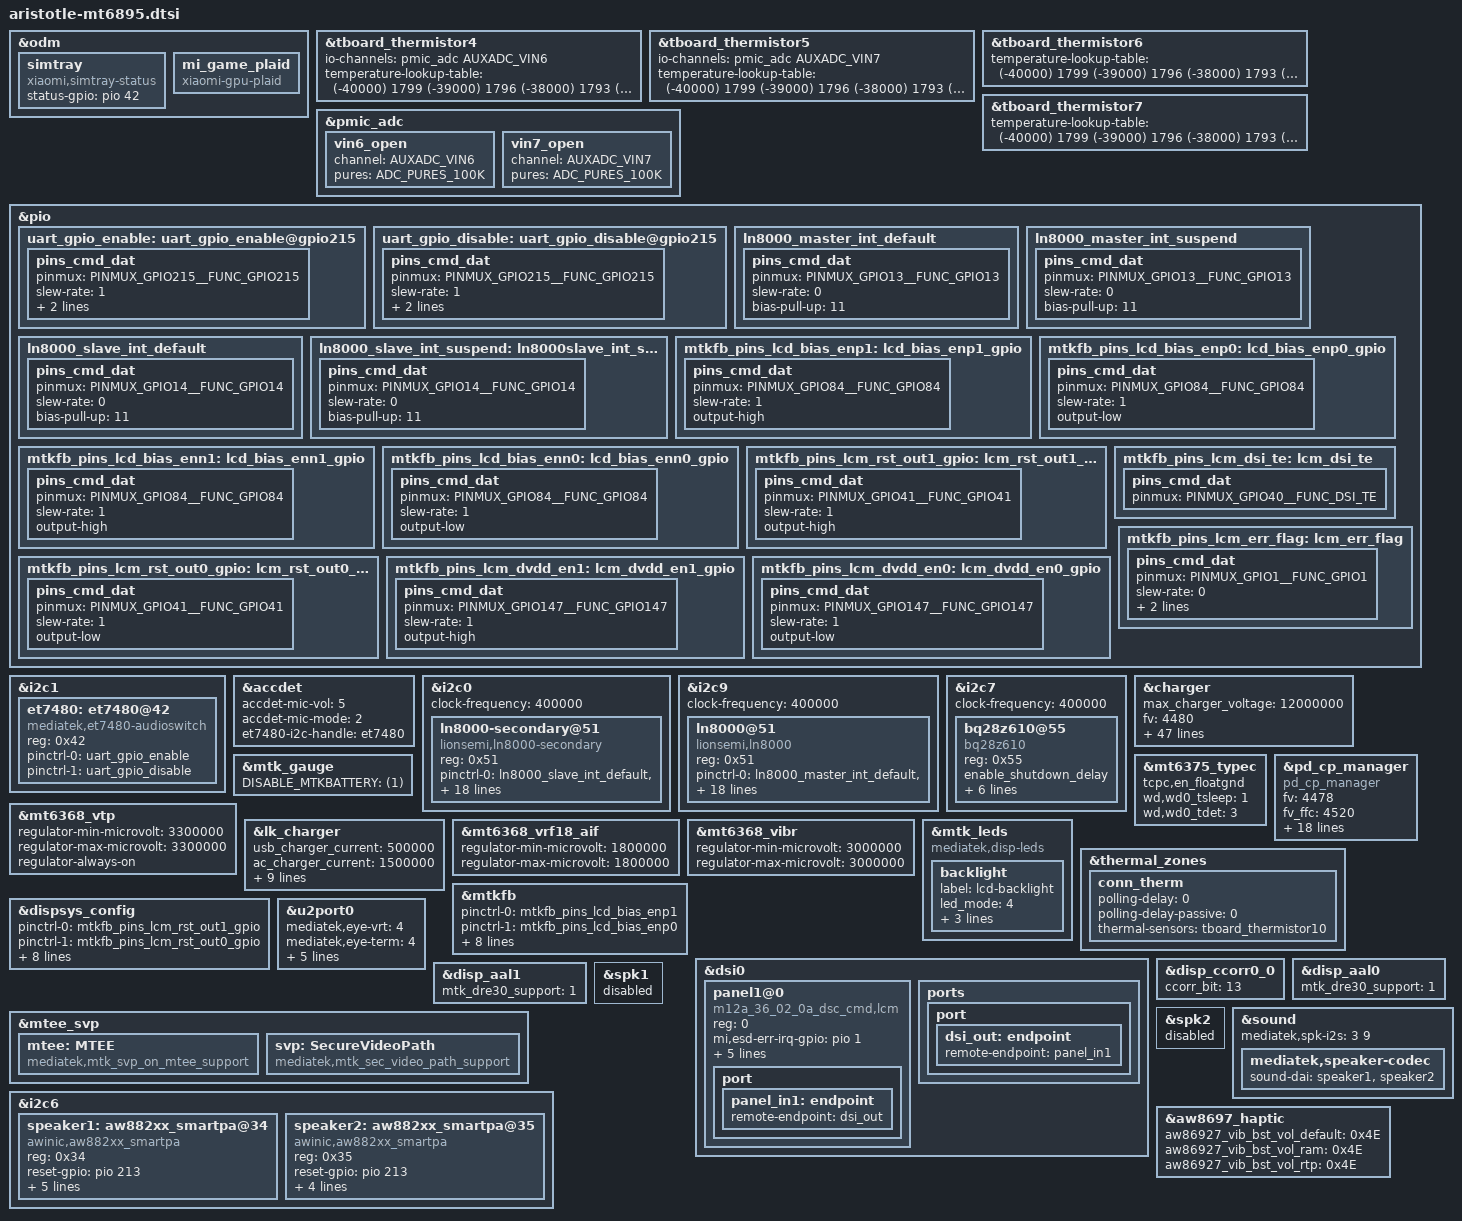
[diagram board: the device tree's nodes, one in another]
/*
this file is only for attribution of aristotle
*/
#include "mediatek/xiaomi-mt6895-common.dtsi"
#include "mediatek/aristotle_mt6895_camera_v4l2.dtsi"
#include "mediatek/xiaomi-aristotle-mt6895-fingerprint.dtsi"
#include "mediatek/xiaomi_aristotle_mt6895_touch.dtsi"
#include <dt-bindings/iio/mt635x-auxadc.h>
#include <dt-bindings/thermal/thermal.h>

&odm {
	simtray {
		compatible = "xiaomi,simtray-status";
		status-gpio =	<&pio 42 0>;
	};
};
&tboard_thermistor4{
	io-channels =<&pmic_adc AUXADC_VIN6>;
	temperature-lookup-table = <
		(-40000) 1799
		(-39000) 1796
		(-38000) 1793
		(-37000) 1790
		(-36000) 1786
		(-35000) 1783
		(-34000) 1779
		(-33000) 1775
		(-32000) 1769
		(-31000) 1765
		(-30000) 1760
		(-29000) 1754
		(-28000) 1749
		(-27000) 1743
		(-26000) 1737
		(-25000) 1731
		(-24000) 1723
		(-23000) 1716
		(-22000) 1709
		(-21000) 1701
		(-20000) 1693
		(-19000) 1685
		(-18000) 1675
		(-17000) 1666
		(-16000) 1656
		(-15000) 1646
		(-14000) 1635
		(-13000) 1623
		(-12000) 1612
		(-11000) 1600
		(-10000) 1588
		(-9000) 1574
		(-8000) 1561
		(-7000) 1548
		(-6000) 1533
		(-5000) 1518
		(-4000) 1503
		(-3000) 1487
		(-2000) 1471
		(-1000) 1455
		0 1437
		1000 1420
		2000 1402
		3000 1384
		4000 1365
		5000 1346
		6000 1327
		7000 1307
		8000 1287
		9000 1267
		10000 1246
		11000 1225
		12000 1204
		13000 1183
		14000 1161
		15000 1140
		16000 1117
		17000 1096
		18000 1073
		19000 1052
		20000 1029
		21000 1008
		22000 985
		23000 964
		24000 941
		25000 920
		26000 899
		27000 877
		28000 856
		29000 834
		30000 814
		31000 792
		32000 772
		33000 752
		34000 732
		35000 712
		36000 693
		37000 674
		38000 655
		39000 637
		40000 618
		41000 601
		42000 584
		43000 567
		44000 550
		45000 535
		46000 518
		47000 503
		48000 488
		49000 473
		50000 459
		51000 445
		52000 431
		53000 418
		54000 405
		55000 393
		56000 380
		57000 368
		58000 357
		59000 346
		60000 334
		61000 324
		62000 314
		63000 304
		64000 294
		65000 285
		66000 276
		67000 267
		68000 259
		69000 250
		70000 242
		71000 235
		72000 227
		73000 220
		74000 214
		75000 206
		76000 200
		77000 193
		78000 187
		79000 182
		80000 176
		81000 171
		82000 165
		83000 159
		84000 154
		85000 150
		86000 145
		87000 141
		88000 136
		89000 132
		90000 128
		91000 124
		92000 121
		93000 117
		94000 113
		95000 109
		96000 106
		97000 103
		98000 100
		99000 97
		100000 94
		101000 91
		102000 89
		103000 86
		104000 83
		105000 81
		106000 79
		107000 76
		108000 74
		109000 72
		110000 70
		111000 67
		112000 65
		113000 63
		114000 62
		115000 60
		116000 58
		117000 57
		118000 55
		119000 53
		120000 52
		121000 51
		122000 49
		123000 48
		124000 47
		125000 45>;
};
&tboard_thermistor5{
	io-channels =<&pmic_adc AUXADC_VIN7>;
	temperature-lookup-table = <
		(-40000) 1799
		(-39000) 1796
		(-38000) 1793
		(-37000) 1790
		(-36000) 1786
		(-35000) 1783
		(-34000) 1779
		(-33000) 1775
		(-32000) 1769
		(-31000) 1765
		(-30000) 1760
		(-29000) 1754
		(-28000) 1749
		(-27000) 1743
		(-26000) 1737
		(-25000) 1731
		(-24000) 1723
		(-23000) 1716
		(-22000) 1709
		(-21000) 1701
		(-20000) 1693
		(-19000) 1685
		(-18000) 1675
		(-17000) 1666
		(-16000) 1656
		(-15000) 1646
		(-14000) 1635
		(-13000) 1623
		(-12000) 1612
		(-11000) 1600
		(-10000) 1588
		(-9000) 1574
		(-8000) 1561
		(-7000) 1548
		(-6000) 1533
		(-5000) 1518
		(-4000) 1503
		(-3000) 1487
		(-2000) 1471
		(-1000) 1455
		0 1437
		1000 1420
		2000 1402
		3000 1384
		4000 1365
		5000 1346
		6000 1327
		7000 1307
		8000 1287
		9000 1267
		10000 1246
		11000 1225
		12000 1204
		13000 1183
		14000 1161
		15000 1140
		16000 1117
		17000 1096
		18000 1073
		19000 1052
		20000 1029
		21000 1008
		22000 985
		23000 964
		24000 941
		25000 920
		26000 899
		27000 877
		28000 856
		29000 834
		30000 814
		31000 792
		32000 772
		33000 752
		34000 732
		35000 712
		36000 693
		37000 674
		38000 655
		39000 637
		40000 618
		41000 601
		42000 584
		43000 567
		44000 550
		45000 535
		46000 518
		47000 503
		48000 488
		49000 473
		50000 459
		51000 445
		52000 431
		53000 418
		54000 405
		55000 393
		56000 380
		57000 368
		58000 357
		59000 346
		60000 334
		61000 324
		62000 314
		63000 304
		64000 294
		65000 285
		66000 276
		67000 267
		68000 259
		69000 250
		70000 242
		71000 235
		72000 227
		73000 220
		74000 214
		75000 206
		76000 200
		77000 193
		78000 187
		79000 182
		80000 176
		81000 171
		82000 165
		83000 159
		84000 154
		85000 150
		86000 145
		87000 141
		88000 136
		89000 132
		90000 128
		91000 124
		92000 121
		93000 117
		94000 113
		95000 109
		96000 106
		97000 103
		98000 100
		99000 97
		100000 94
		101000 91
		102000 89
		103000 86
		104000 83
		105000 81
		106000 79
		107000 76
		108000 74
		109000 72
		110000 70
		111000 67
		112000 65
		113000 63
		114000 62
		115000 60
		116000 58
		117000 57
		118000 55
		119000 53
		120000 52
		121000 51
		122000 49
		123000 48
		124000 47
		125000 45>;
};
&tboard_thermistor6{
	temperature-lookup-table = <
		(-40000) 1799
		(-39000) 1796
		(-38000) 1793
		(-37000) 1790
		(-36000) 1786
		(-35000) 1783
		(-34000) 1779
		(-33000) 1775
		(-32000) 1769
		(-31000) 1765
		(-30000) 1760
		(-29000) 1754
		(-28000) 1749
		(-27000) 1743
		(-26000) 1737
		(-25000) 1731
		(-24000) 1723
		(-23000) 1716
		(-22000) 1709
		(-21000) 1701
		(-20000) 1693
		(-19000) 1685
		(-18000) 1675
		(-17000) 1666
		(-16000) 1656
		(-15000) 1646
		(-14000) 1635
		(-13000) 1623
		(-12000) 1612
		(-11000) 1600
		(-10000) 1588
		(-9000) 1574
		(-8000) 1561
		(-7000) 1548
		(-6000) 1533
		(-5000) 1518
		(-4000) 1503
		(-3000) 1487
		(-2000) 1471
		(-1000) 1455
		0 1437
		1000 1420
		2000 1402
		3000 1384
		4000 1365
		5000 1346
		6000 1327
		7000 1307
		8000 1287
		9000 1267
		10000 1246
		11000 1225
		12000 1204
		13000 1183
		14000 1161
		15000 1140
		16000 1117
		17000 1096
		18000 1073
		19000 1052
		20000 1029
		21000 1008
		22000 985
		23000 964
		24000 941
		25000 920
		26000 899
		27000 877
		28000 856
		29000 834
		30000 814
		31000 792
		32000 772
		33000 752
		34000 732
		35000 712
		36000 693
		37000 674
		38000 655
		39000 637
		40000 618
		41000 601
		42000 584
		43000 567
		44000 550
		45000 535
		46000 518
		47000 503
		48000 488
		49000 473
		50000 459
		51000 445
		52000 431
		53000 418
		54000 405
		55000 393
		56000 380
		57000 368
		58000 357
		59000 346
		60000 334
		61000 324
		62000 314
		63000 304
		64000 294
		65000 285
		66000 276
		67000 267
		68000 259
		69000 250
		70000 242
		71000 235
		72000 227
		73000 220
		74000 214
		75000 206
		76000 200
		77000 193
		78000 187
		79000 182
		80000 176
		81000 171
		82000 165
		83000 159
		84000 154
		85000 150
		86000 145
		87000 141
		88000 136
		89000 132
		90000 128
		91000 124
		92000 121
		93000 117
		94000 113
		95000 109
		96000 106
		97000 103
		98000 100
		99000 97
		100000 94
		101000 91
		102000 89
		103000 86
		104000 83
		105000 81
		106000 79
		107000 76
		108000 74
		109000 72
		110000 70
		111000 67
		112000 65
		113000 63
		114000 62
		115000 60
		116000 58
		117000 57
		118000 55
		119000 53
		120000 52
		121000 51
		122000 49
		123000 48
		124000 47
		125000 45>;
};
&tboard_thermistor7{
	temperature-lookup-table = <
		(-40000) 1799
		(-39000) 1796
		(-38000) 1793
		(-37000) 1790
		(-36000) 1786
		(-35000) 1783
		(-34000) 1779
		(-33000) 1775
		(-32000) 1769
		(-31000) 1765
		(-30000) 1760
		(-29000) 1754
		(-28000) 1749
		(-27000) 1743
		(-26000) 1737
		(-25000) 1731
		(-24000) 1723
		(-23000) 1716
		(-22000) 1709
		(-21000) 1701
		(-20000) 1693
		(-19000) 1685
		(-18000) 1675
		(-17000) 1666
		(-16000) 1656
		(-15000) 1646
		(-14000) 1635
		(-13000) 1623
		(-12000) 1612
		(-11000) 1600
		(-10000) 1588
		(-9000) 1574
		(-8000) 1561
		(-7000) 1548
		(-6000) 1533
		(-5000) 1518
		(-4000) 1503
		(-3000) 1487
		(-2000) 1471
		(-1000) 1455
		0 1437
		1000 1420
		2000 1402
		3000 1384
		4000 1365
		5000 1346
		6000 1327
		7000 1307
		8000 1287
		9000 1267
		10000 1246
		11000 1225
		12000 1204
		13000 1183
		14000 1161
		15000 1140
		16000 1117
		17000 1096
		18000 1073
		19000 1052
		20000 1029
		21000 1008
		22000 985
		23000 964
		24000 941
		25000 920
		26000 899
		27000 877
		28000 856
		29000 834
		30000 814
		31000 792
		32000 772
		33000 752
		34000 732
		35000 712
		36000 693
		37000 674
		38000 655
		39000 637
		40000 618
		41000 601
		42000 584
		43000 567
		44000 550
		45000 535
		46000 518
		47000 503
		48000 488
		49000 473
		50000 459
		51000 445
		52000 431
		53000 418
		54000 405
		55000 393
		56000 380
		57000 368
		58000 357
		59000 346
		60000 334
		61000 324
		62000 314
		63000 304
		64000 294
		65000 285
		66000 276
		67000 267
		68000 259
		69000 250
		70000 242
		71000 235
		72000 227
		73000 220
		74000 214
		75000 206
		76000 200
		77000 193
		78000 187
		79000 182
		80000 176
		81000 171
		82000 165
		83000 159
		84000 154
		85000 150
		86000 145
		87000 141
		88000 136
		89000 132
		90000 128
		91000 124
		92000 121
		93000 117
		94000 113
		95000 109
		96000 106
		97000 103
		98000 100
		99000 97
		100000 94
		101000 91
		102000 89
		103000 86
		104000 83
		105000 81
		106000 79
		107000 76
		108000 74
		109000 72
		110000 70
		111000 67
		112000 65
		113000 63
		114000 62
		115000 60
		116000 58
		117000 57
		118000 55
		119000 53
		120000 52
		121000 51
		122000 49
		123000 48
		124000 47
		125000 45>;
};
&pmic_adc {
	vin6_open {
		channel = <AUXADC_VIN6>;
		pures = <ADC_PURES_100K>;
	};
	vin7_open {
		channel = <AUXADC_VIN7>;
		pures = <ADC_PURES_100K>;
	};
};
/* Audio Switch start */
&pio {
        uart_gpio_enable: uart_gpio_enable@gpio215 {
                pins_cmd_dat {
                        pinmux = <PINMUX_GPIO215__FUNC_GPIO215>;
                        slew-rate = <1>;
                        bias-disable;
                        output-low;
                };
        };
        uart_gpio_disable: uart_gpio_disable@gpio215 {
                pins_cmd_dat {
                        pinmux = <PINMUX_GPIO215__FUNC_GPIO215>;
                        slew-rate = <1>;
                        bias-disable;
                        output-high;
                };
        };
	// ln8000-master
	ln8000_master_int_default: ln8000_master_int_default {
		pins_cmd_dat {
			pinmux = <PINMUX_GPIO13__FUNC_GPIO13>;
			slew-rate = <0>;
			bias-pull-up = <11>;
		};
	};
	ln8000_master_int_suspend: ln8000_master_int_suspend {
		pins_cmd_dat {
			pinmux = <PINMUX_GPIO13__FUNC_GPIO13>;
			slew-rate = <0>;
			bias-pull-up = <11>;
		};
	};
	// ln8000-slave
	ln8000_slave_int_default: ln8000_slave_int_default {
		pins_cmd_dat {
			pinmux = <PINMUX_GPIO14__FUNC_GPIO14>;
			slew-rate = <0>;
			bias-pull-up = <11>;
		};
	};
	ln8000_slave_int_suspend: ln8000slave_int_suspend {
		pins_cmd_dat {
			pinmux = <PINMUX_GPIO14__FUNC_GPIO14>;
			slew-rate = <0>;
			bias-pull-up = <11>;
		};
	};
};
&i2c1 {
        et7480: et7480@42 {
                status = "ok";
                compatible = "mediatek,et7480-audioswitch";
                reg = <0x42>;
                pinctrl-names = "uart_enable", "uart_disable";
                pinctrl-0 = <&uart_gpio_enable>;
                pinctrl-1 = <&uart_gpio_disable>;
        };
};
&accdet {
        /* accdet micbias voltage: 0x09:2.85v 0x08:2.8v 0x07,
         * 2.7v;0x05,2.5v;0x02,1.9v
         */
        accdet-mic-vol = <5>;
        /*1:ACC mode, 2:low cost without in bias, 6:low cost with in bias*/
        accdet-mic-mode = <2>;
        et7480-i2c-handle = <&et7480>;
};
/* Audio Swtich end */
&i2c0 {
	clock-frequency = <400000>;
	status = "okay";
	ln8000-secondary@51 {
		compatible = "lionsemi,ln8000-secondary";
		reg = <0x51>;
		pinctrl-names = "ln8000_slave_irq";
		pinctrl-0 = <&ln8000_slave_int_default &ln8000_slave_int_suspend>;
		charger_name = "quaternary_chg";
		/* bank <bit-idx> <flags: active-low> */
		//irq-gpios = <&tlmm 55 0x2002>;
		//interrupt-parent = <&tlmm>;
		//interrupts = <55 0x2002>;
		//pinctrl-names = "default";
		//pinctrl-0 = <&ln8000_int_default &ln8000_int_suspend>;
		//ln8000_charger,irq_index = <296>;
		ln8000_irq_gpio = <&pio 14 0x0>;
		/* device configuration */
		ln8000_charger,bat-ovp-threshold = <4660>;
		ln8000_charger,bat-ovp-alarm-threshold = <4625>;
		ln8000_charger,bus-ovp-threshold = <13000>;
		ln8000_charger,bus-ovp-alarm-threshold = <11000>;
		ln8000_charger,bus-ocp-threshold = <3750>;
		ln8000_charger,bus-ocp-alarm-threshold = <3500>;
		ln8000_charger,ntc-alarm-cfg  = <226>;
		/* protection enable/disable flags
		 *   vbat-ovp-disable
		 *   vbat-reg-disable
		 *   iin-ocp-disable
		 *   iin-reg-disable
		 *   tbus-mon-disable
		 *   tbat-mon-disable
		 *   tdie-prot-disable
		 *   tdie-reg-disable
		 *   revcurr-prot-disable
		 */
		ln8000_charger,tdie-prot-disable;
		ln8000_charger,tbus-mon-disable;
		ln8000_charger,tbat-mon-disable;
		ln8000_charger,iin-ocp-disable;
		ln8000_charger,iin-reg-disable;
		ln8000_charger,tdie-reg-disable;
		ln8000_charger,vbat-reg-disable;
		ln8000_charger,reset-prevent-enable;
	};
};

&i2c9 {
	clock-frequency = <400000>;
	status = "okay";
	ln8000@51 {
		compatible = "lionsemi,ln8000";
		reg = <0x51>;
		/* bank <bit-idx> <flags: active-low> */
		//irq-gpios = <&tlmm 55 0x2002>;
		pinctrl-names = "ln8000_master_irq";
		pinctrl-0 = <&ln8000_master_int_default &ln8000_master_int_suspend>;
		charger_name = "tertiary_chg";
		//interrupt-parent = <&tlmm>;
		//interrupts = <55 0x2002>;
		//pinctrl-names = "default";
		//pinctrl-0 = <&ln8000_int_default ln8000_int_suspend>;
		//ln8000_charger,irq_index = <296>;
		ln8000_irq_gpio = <&pio 13 0x0>;
		/* device configuration */
		ln8000_charger,bat-ovp-threshold = <4660>;
		ln8000_charger,bat-ovp-alarm-threshold = <4625>;
		ln8000_charger,bus-ovp-threshold = <13000>;
		ln8000_charger,bus-ovp-alarm-threshold = <11000>;
		ln8000_charger,bus-ocp-threshold = <3750>;
		ln8000_charger,bus-ocp-alarm-threshold = <3500>;
		ln8000_charger,ntc-alarm-cfg  = <226>;
		/* protection enable/disable flags
		 *   vbat-ovp-disable
		 *   vbat-reg-disable
		 *   iin-ocp-disable
		 *   iin-reg-disable
		 *   tbus-mon-disable
		 *   tbat-mon-disable
		 *   tdie-prot-disable
		 *   tdie-reg-disable
		 *   revcurr-prot-disable
		 */
		ln8000_charger,tdie-prot-disable;
		ln8000_charger,tbus-mon-disable;
		ln8000_charger,tbat-mon-disable;
		ln8000_charger,iin-ocp-disable;
		ln8000_charger,iin-reg-disable;
		ln8000_charger,tdie-reg-disable;
		ln8000_charger,vbat-reg-disable;
		ln8000_charger,reset-prevent-enable;
	};
};

&i2c7 {
	clock-frequency = <400000>;
	status = "okay";
	bq28z610@55 {
		compatible = "bq28z610";
		reg = <0x55>;
		enable_shutdown_delay;
		normal_shutdown_vbat_1s = <3400>;
		critical_shutdown_vbat_1s = <3340>;
		report_full_rsoc_1s = <9700>;
		soc_gap_1s = <2>;
		soc_decimal_rate = <
			0  38
			10 35
			20 33
			30 33
			40 33
			50 33
			60 33
			70 30
			80 25
			90 20
			95 10 >;
	};
};

&charger {
		max_charger_voltage = <12000000>;
		fv = <4480>;
		fv_ffc = <4530>;
		iterm = <246>;
		iterm_warm = <246>;
		iterm_ffc = <1230>;
		iterm_ffc_warm = <1328>;
		iterm_2nd = <246>;
		iterm_warm_2nd = <246>;
		iterm_ffc_2nd = <1082>;
		iterm_ffc_warm_2nd = <1230>;
		/* charging current */
		usb_charger_current = <500000>;
		ac_charger_current = <1500000>;
		ac_charger_input_current = <1500000>;
		charging_host_charger_current = <1500000>;
		ffc_low_tbat = <150>;
		ffc_high_tbat = <480>;
		ffc_medium_tbat = <350>;
		ffc_high_soc = <95>;
		step_fallback_hyst = <25>;
		step_forward_hyst = <5>;
		jeita_fallback_hyst = <10>;
		jeita_forward_hyst = <10>;
		burn_control_gpio = <&pio 193 0x0>;
		en_floatgnd;
		aristotle_product;
		pd2_input_current = <1700000>;
		jeita_fcc_cfg = <(-100)	0	4150	1000	738
				1	50	4150	2360	2360
				51	100	4150	3344	3344
				101	150	4150	5804	5804
				151	470	4150	12200	12200
				471	600	4100	2360	2360>;
		jeita_fv_cfg = <(-100)	0	4480
				1	50	4480
				51	100	4480
				101	150	4480
				151	470	4530
				471	600	4100>;
		step_chg_cfg_low_cycle = <3000	4250	12200
					4251	4300	8756
					4301	4480	7280
					4481	4530	5804>;
		step_chg_cfg_middle_cycle = <3000	4200	12200
					4201	4250	8756
					4251	4480	7280
					4481	4530	5804>;
		step_chg_cfg_high_cycle = <3000	4200	12200
					4201	4250	8756
					4251	4460	7280
					4461	4510	5804>;
		thermal_limit_dcp = <1600 1600 1600 1600 1600 1600 1600 1600 1600 1600 1600 1600 1500 1400 1200 500>;
		thermal_limit_qc2 = <2500 2500 2500 2500 2500 2500 2500 2500 2500 2500 2500 2000 1500 1500 1000 500>;
		thermal_limit_qc3_18w = <2500 2500 2500 2500 2500 2500 2400 2300 2200 2100 1500 1000 800 700 600 500>;
		thermal_limit_qc3_27w = <2500 2500 2500 2500 2500 2500 2400 2300 2200 2100 1500 1000 800 700 600 500>;
		thermal_limit_qc35 = <2500 2500 2500 2500 2500 2500 2400 2300 2200 2100 1500 1000 800 700 600 500>;
		thermal_limit_pd = <12400 10000 10000 9000 8000 8000 7000 6600 6000 5000 5000 4000 2900 2000 1000 500>;
};
&mtk_gauge {
        DISABLE_MTKBATTERY = <(1)>;
};
&mt6375_typec {
	tcpc,en_floatgnd;
	/* 0:16x, 1:128x, 2:512x, 3:1024x */
	wd,wd0_tsleep = <1>;
	/* 0:400us, 1:1ms, 2:2ms, 3:4ms, 4:10ms, 5:40ms, 6:100ms, 7:400ms */
	wd,wd0_tdet = <3>;
	/* example wd0_tsleep = 512x, wd0_tdet = 4ms, wd0 polling time = 512*4ms */
};
&mt6368_vtp {
	regulator-min-microvolt = <3300000>;
	regulator-max-microvolt = <3300000>;
	regulator-always-on;
};
&lk_charger {
		/* charging current */
		usb_charger_current = <500000>;
		ac_charger_current = <1500000>;
		ac_charger_input_current = <2000000>;
		non_std_ac_charger_current = <1500000>;
		charging_host_charger_current = <1500000>;
		ta_ac_charger_current = <1500000>;
		pd_charger_current = <1500000>;
		/* battery temperature protection */
		temp_t4_threshold = <60>;
		temp_t3_threshold = <45>;
		pre_charger_current = <250000>;
		fast_charge_voltage = <3100>;
};
&pd_cp_manager {
		compatible = "pd_cp_manager";
		fv = <4478>;
		fv_ffc = <4520>;
		max_fcc = <12400>;
		max_vbus = <12000>;
		max_ibus = <6200>;
		fcc_low_hyst = <150>;
		fcc_high_hyst = <10>;
		low_tbat = <100>;
		high_tbat = <480>;
		high_vbat = <4400>;
		high_soc = <95>;
		low_fcc = <2000>;
		cv_vbat = <4480>;
		cv_vbat_ffc = <4510>;
		cv_ibat = <2000>;
		cv_ibat_bypass = <1800>;
		vbus_low_gap_div = <400>;
		vbus_high_gap_div = <600>;
		min_pdo_vbus = <8000>;
		max_pdo_vbus = <11000>;
};
&mt6368_vrf18_aif {
	regulator-min-microvolt = <1800000>;
	regulator-max-microvolt = <1800000>;
};
&mt6368_vibr {
	regulator-min-microvolt = <3000000>;
	regulator-max-microvolt = <3000000>;
};
&mtk_leds {
	compatible = "mediatek,disp-leds";
	backlight {
		label = "lcd-backlight";
		led_mode = <4>;
		max-brightness = <4095>;
		max-hw-brightness = <4095>;
		default-state = "quarter";
	};
};
&thermal_zones {
		conn_therm: conn_therm {
			polling-delay = <0>;
			polling-delay-passive = <0>;
			thermal-sensors = <&tboard_thermistor10>;
		};
};
&odm {
	mi_game_plaid {
		compatible = "xiaomi-gpu-plaid";
	};
};
&pio {
	mtkfb_pins_lcd_bias_enp1: lcd_bias_enp1_gpio {
		pins_cmd_dat {
			pinmux = <PINMUX_GPIO84__FUNC_GPIO84>;
			slew-rate = <1>;
			output-high;
		};
	};
	mtkfb_pins_lcd_bias_enp0: lcd_bias_enp0_gpio {
		pins_cmd_dat {
			pinmux = <PINMUX_GPIO84__FUNC_GPIO84>;
			slew-rate = <1>;
			output-low;
		};
	};
	mtkfb_pins_lcd_bias_enn1: lcd_bias_enn1_gpio {
		pins_cmd_dat {
			pinmux = <PINMUX_GPIO84__FUNC_GPIO84>;
			slew-rate = <1>;
			output-high;
		};
	};
	mtkfb_pins_lcd_bias_enn0: lcd_bias_enn0_gpio {
		pins_cmd_dat {
			pinmux = <PINMUX_GPIO84__FUNC_GPIO84>;
			slew-rate = <1>;
			output-low;

		};
	};
	mtkfb_pins_lcm_rst_out1_gpio: lcm_rst_out1_gpio {
		pins_cmd_dat {
			pinmux = <PINMUX_GPIO41__FUNC_GPIO41>;
			slew-rate = <1>;
			output-high;
		};
	};
	mtkfb_pins_lcm_rst_out0_gpio: lcm_rst_out0_gpio {
		pins_cmd_dat {
			pinmux = <PINMUX_GPIO41__FUNC_GPIO41>;
			slew-rate = <1>;
			output-low;
		};
	};
	mtkfb_pins_lcm_dsi_te: lcm_dsi_te {
		pins_cmd_dat {
			pinmux = <PINMUX_GPIO40__FUNC_DSI_TE>;
		};
	};
	mtkfb_pins_lcm_dvdd_en1: lcm_dvdd_en1_gpio {
		pins_cmd_dat {
			pinmux = <PINMUX_GPIO147__FUNC_GPIO147>;
			slew-rate = <1>;
			output-high;
		};
	};
	mtkfb_pins_lcm_dvdd_en0: lcm_dvdd_en0_gpio {
		pins_cmd_dat {
			pinmux = <PINMUX_GPIO147__FUNC_GPIO147>;
			slew-rate = <1>;
			output-low;
		};
	};
	mtkfb_pins_lcm_err_flag: lcm_err_flag {
		pins_cmd_dat {
			pinmux = <PINMUX_GPIO1__FUNC_GPIO1>;
			slew-rate = <0>;
			bias-pull-up = <11>;
                        input-enable;
		};
	};
};
&mtkfb {
	pinctrl-names = "lcd_bias_enp1_gpio", "lcd_bias_enp0_gpio",
		"lcd_bias_enn1_gpio", "lcd_bias_enn0_gpio",
		"lcm_rst_out1_gpio", "lcm_rst_out0_gpio",
		"mode_te_te", "lcm_dvdd_en1_gpio",
		"lcm_dvdd_en0_gpio", "err_flag_init";
	pinctrl-0 = <&mtkfb_pins_lcd_bias_enp1>;
	pinctrl-1 = <&mtkfb_pins_lcd_bias_enp0>;
	pinctrl-2 = <&mtkfb_pins_lcd_bias_enn1>;
	pinctrl-3 = <&mtkfb_pins_lcd_bias_enn0>;
	pinctrl-4 = <&mtkfb_pins_lcm_rst_out1_gpio>;
	pinctrl-5 = <&mtkfb_pins_lcm_rst_out0_gpio>;
	pinctrl-6 = <&mtkfb_pins_lcm_dsi_te>;
	pinctrl-7 = <&mtkfb_pins_lcm_dvdd_en1>;
	pinctrl-8 = <&mtkfb_pins_lcm_dvdd_en0>;
	pinctrl-9 = <&mtkfb_pins_lcm_err_flag>;
	status = "okay";
};
&dispsys_config {
	pinctrl-names =
		"lcm_rst_out1_gpio", "lcm_rst_out0_gpio",
		"mode_te_te", "lcm_dvdd_en1_gpio",
		"lcm_dvdd_en0_gpio", "err_flag_init";
	pinctrl-0 = <&mtkfb_pins_lcm_rst_out1_gpio>;
	pinctrl-1 = <&mtkfb_pins_lcm_rst_out0_gpio>;
	pinctrl-2 = <&mtkfb_pins_lcm_dsi_te>;
	pinctrl-3 = <&mtkfb_pins_lcm_dvdd_en1>;
	pinctrl-4 = <&mtkfb_pins_lcm_dvdd_en0>;
	pinctrl-5 = <&mtkfb_pins_lcm_err_flag>;
	status = "okay";

	helper-value = <0>, /*MTK_DRM_OPT_STAGE*/
	<1>, /*MTK_DRM_OPT_USE_CMDQ*/
	<1>, /*MTK_DRM_OPT_USE_M4U*/
	<1>, /*MTK_DRM_OPT_MMQOS_SUPPORT*/
	<1>, /*MTK_DRM_OPT_MMDVFS_SUPPORT*/
	<1>, /*MTK_DRM_OPT_SODI_SUPPORT*/
	<1>, /*MTK_DRM_OPT_IDLE_MGR*/
	<0>, /*MTK_DRM_OPT_IDLEMGR_SWTCH_DECOUPLE*/
	<1>, /*MTK_DRM_OPT_IDLEMGR_BY_REPAINT*/
	<0>, /*MTK_DRM_OPT_IDLEMGR_ENTER_ULPS*/
	<0>, /*MTK_DRM_OPT_IDLEMGR_KEEP_LP11*/
	<1>, /*MTK_DRM_OPT_DYNAMIC_RDMA_GOLDEN_SETTING*/
	<1>, /*MTK_DRM_OPT_IDLEMGR_DISABLE_ROUTINE_IRQ*/
	<0>, /*MTK_DRM_OPT_MET_LOG*/
	<1>, /*MTK_DRM_OPT_USE_PQ*/
	<1>, /*MTK_DRM_OPT_ESD_CHECK_RECOVERY*/
	<0>, /*MTK_DRM_OPT_ESD_CHECK_SWITCH*/
	<1>, /*MTK_DRM_OPT_PRESENT_FENCE*/
	<0>, /*MTK_DRM_OPT_RDMA_UNDERFLOW_AEE*/
	<1>, /*MTK_DRM_OPT_DSI_UNDERRUN_AEE*/
	<1>, /*MTK_DRM_OPT_HRT*/
	<1>, /*MTK_DRM_OPT_HRT_MODE*/
	<0>, /*MTK_DRM_OPT_DELAYED_TRIGGER*/
	<1>, /*MTK_DRM_OPT_OVL_EXT_LAYER*/
	<1>, /*MTK_DRM_OPT_AOD*/
	<1>, /*MTK_DRM_OPT_RPO*/
	<0>, /*MTK_DRM_OPT_DUAL_PIPE*/
	<0>, /*MTK_DRM_OPT_DC_BY_HRT*/
	<0>, /*MTK_DRM_OPT_OVL_WCG*/
	<0>, /*MTK_DRM_OPT_OVL_SBCH*/
	<1>, /*MTK_DRM_OPT_COMMIT_NO_WAIT_VBLANK*/
	<0>, /*MTK_DRM_OPT_MET*/
	<0>, /*MTK_DRM_OPT_REG_PARSER_RAW_DUMP*/
	<0>, /*MTK_DRM_OPT_VP_PQ*/
	<0>, /*MTK_DRM_OPT_GAME_PQ*/
	<0>, /*MTK_DRM_OPT_MMPATH*/
	<0>, /*MTK_DRM_OPT_HBM*/
	<0>, /*MTK_DRM_OPT_VDS_PATH_SWITCH*/
	<0>, /*MTK_DRM_OPT_LAYER_REC*/
	<1>, /*MTK_DRM_OPT_CLEAR_LAYER*/
	<1>, /*MTK_DRM_OPT_LFR*/
	<0>, /*MTK_DRM_OPT_SF_PF*/
	<0>, /*MTK_DRM_OPT_DYN_MIPI_CHANGE*/
	<1>, /*MTK_DRM_OPT_PRIM_DUAL_PIPE*/
	<1>, /*MTK_DRM_OPT_MSYNC2_0*/
	<1>, /*MTK_DRM_OPT_MML_PRIMARY*/
	<0>, /*MTK_DRM_OPT_DUAL_TE*/
	<1>, /*MTK_DRM_OPT_VIRTUAL_DISP*/
	<1>; /*MTK_DRM_OPT_RES_SWITCH*/
};
&dsi0 {
	status = "okay";
	#address-cells = <1>;
	#size-cells = <0>;
	panel1@0 {
		compatible = "m12a_36_02_0a_dsc_cmd,lcm";
		reg = <0>;
		mi,esd-err-irq-gpio = <&pio 1 0x2002>;
		reset-gpios = <&pio 41 0>;
		dvdd-gpios = <&pio 147 0>;
		cam-gpios = <&pio 158 0>;
		vibr-supply = <&mt6368_vibr>;
		vrf18-supply = <&mt6368_vrf18_aif>;
		pinctrl-names = "default";
		port {
			panel_in1: endpoint {
				remote-endpoint = <&dsi_out>;
			};
		};
	};

	ports {
		port {
			dsi_out: endpoint {
				remote-endpoint = <&panel_in1>;
			};
		};
	};
};
&u2port0{
	mediatek,eye-vrt = <4>;
	mediatek,eye-term = <4>;
	mediatek,rev6 = <2>;
	mediatek,discth = <0xb>;
	mediatek,eye-term-host = <7>;
	mediatek,eye-vrt-host = <7>;
	mediatek,rev6-host = <2>;
};
&disp_ccorr0_0 {
	ccorr_bit = <13>;
};
&disp_aal0 {
	mtk_dre30_support = <1>;
};
&disp_aal1 {
	mtk_dre30_support = <1>;
};
&mtee_svp {
	mtee: MTEE {
                   compatible = "mediatek,mtk_svp_on_mtee_support";
	};
	svp: SecureVideoPath {
                   compatible = "mediatek,mtk_sec_video_path_support";
	};
};

&spk1 {
	status = "disabled";
};

&spk2 {
	status = "disabled";
};

&i2c6 {
	speaker1: aw882xx_smartpa@34 {
		compatible = "awinic,aw882xx_smartpa";
		#sound-dai-cells = <0>;
		reg = <0x34>;
		reset-gpio = <&pio 213 0>;
		irq-gpio = <&pio 15 0x0>;
		spk-sw-gpio = <&pio 160 0x0>;
		sound-channel = <0>;
		aw-re-min = <4000>;
		aw-re-max= <30000>;
		/*aw-cali-mode = "none";*/
		status = "okay";
	};

        speaker2: aw882xx_smartpa@35 {
		compatible = "awinic,aw882xx_smartpa";
		#sound-dai-cells = <0>;
		reg = <0x35>;
		reset-gpio = <&pio 213 0>;
		irq-gpio = <&pio 19 0x0>;
		sound-channel = <1>;
		aw-re-min = <4000>;
		aw-re-max= <30000>;
		/*aw-cali-mode = "none";*/
		status = "okay";
        };
};

&sound {
	mediatek,spk-i2s = <3 9>;
	mediatek,speaker-codec {
		sound-dai = <&speaker1>, <&speaker2>;
	};
};

&aw8697_haptic {
	aw86927_vib_bst_vol_default = < 0x4E >;
	aw86927_vib_bst_vol_ram = < 0x4E >;
	aw86927_vib_bst_vol_rtp = < 0x4E >;
};
